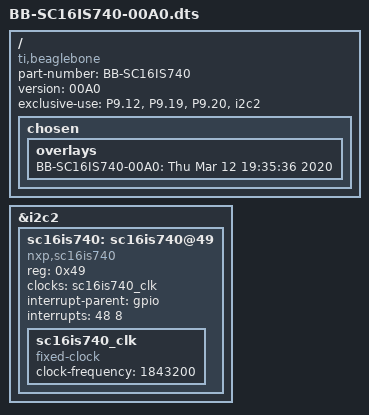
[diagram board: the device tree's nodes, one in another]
/*
 * SPDX-License-Identifier: GPL-2.0-only
 *
 * Description taken from the following pointer:
 * sc16is7xx uart i2c kernel module problems #2241
 * https://github.com/raspberrypi/linux/issues/2241
 *
 * Example taken (and adapted for NXP sc16is740 silicon) from the following pointer:
 * https://github.com/Ysurac/raspberry_kernel_mptcp/blob/master/arch/arm/boot/dts/overlays/sc16is750-i2c-overlay.dts
 */

/dts-v1/;
/plugin/;

/ {
	compatible = "ti,beaglebone", "ti,beaglebone-black";

	// identification
	part-number = "BB-SC16IS740";
	version = "00A0";

	// resources this cape uses
	exclusive-use =
		"P9.12",        // GPIO1_28 = GPIO 60
		"P9.19",        // i2c2_sda
		"P9.20",        // i2c2_scl
		"i2c2";         // hardware ip used

	/*
	 * Helper to show loaded overlays under: /proc/device-tree/chosen/overlays/
	 */
	fragment@0 {
		target-path="/";
		__overlay__ {

			chosen {
				overlays {
					BB-SC16IS740-00A0 = "Thu Mar 12 19:35:36 2020";
				};
			};
		};
	};

	fragment@1 {
		target = <&i2c2>;
		__overlay__ {
			#address-cells = <1>;
			#size-cells = <0>;
			status = "okay";

			sc16is740: sc16is740@49 {
				compatible = "nxp,sc16is740";
				reg = <0x49>; /* address */
				clocks = <&sc16is740_clk>;
				interrupt-parent = <&gpio>;
				interrupts = <48 8>; /* IRQ_TYPE_LEVEL_LOW */
				#gpio-cells = <2>;

				sc16is740_clk: sc16is740_clk {
					compatible = "fixed-clock";
					#clock-cells = <0>;
					clock-frequency = <1843200>;
				};
			};
		};
	};

	__overrides__ {
		int_pin = <&sc16is740>,"interrupts:0";
		addr = <&sc16is740>,"reg:0";
		xtal = <&sc16is740>,"clock-frequency:0";
	};
};
